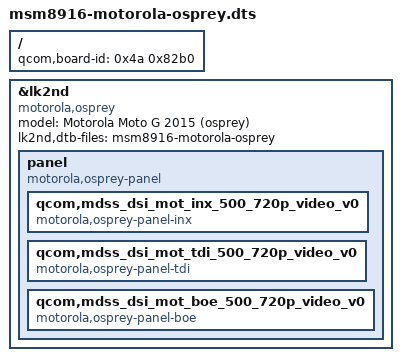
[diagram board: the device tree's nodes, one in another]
// SPDX-License-Identifier: GPL-2.0-only
#include "msm8916-motorola.dtsi"

/ {
	qcom,board-id = <0x4a 0x82b0>;
};

&lk2nd {
	model = "Motorola Moto G 2015 (osprey)";
	compatible = "motorola,osprey";

	lk2nd,dtb-files = "msm8916-motorola-osprey";

	panel {
		compatible = "motorola,osprey-panel", "lk2nd,panel";

		qcom,mdss_dsi_mot_inx_500_720p_video_v0 {
			compatible = "motorola,osprey-panel-inx";
		};
		qcom,mdss_dsi_mot_tdi_500_720p_video_v0 {
			compatible = "motorola,osprey-panel-tdi";
		};
		qcom,mdss_dsi_mot_boe_500_720p_video_v0 {
			compatible = "motorola,osprey-panel-boe";
		};
	};
};
